# PIC32CM1216JH01048 register map
Vendor: Microchip Technology; Series: PIC32CMJH01; File version: 0
CPU: CM0+ r0p0, little endian, MPU, no FPU, VTOR, 2 interrupt priority bits, 32 interrupts
Registers are 32-bit, read-write, reset 0x0 unless marked. A register's access mark holds for its fields unless they carry their own. Offsets are from the block's base; [hi:lo] are bit positions.

## NVMCTRL — Non-Volatile Memory Controller
Base 0x41004000
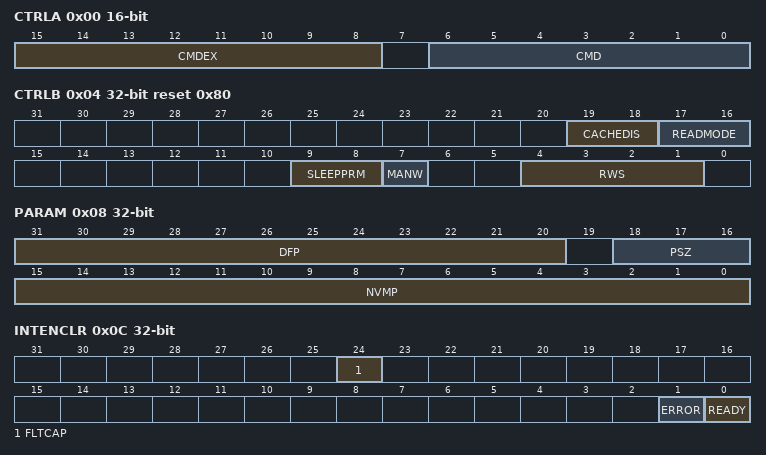
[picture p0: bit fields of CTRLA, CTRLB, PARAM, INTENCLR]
0x00 CTRLA 16-bit — Control A
  [15:8] CMDEX — Command Execution
    165=KEY (Execution Key)
  [6:0] CMD — Command
    2=ER (Erase Row - Erases the row addressed by the ADDR register.); 4=WP (Write Page - Writes the contents of the page buffer to the page addressed by the ADDR register.); 5=EAR (Erase Auxiliary Row - Erases the auxiliary row addressed by the ADDR register. This command can be given only when the security bit is not set and only to the user configuration row.); 6=WAP (Write Auxiliary Page - Writes the contents of the page buffer to the page addressed by the ADDR register. This command can be given only when the security bit is not set and only to the user configuration row.); 26=DFER (Data Flash Erase Row - Erases the row addressed by the ADDR register.); 28=DFWP (Data Flash Write Page - Writes the contents of the page buffer to the page addressed by the ADDR register.); 64=LR (Lock Region - Locks the region containing the address location in the ADDR register.); 65=UR (Unlock Region - Unlocks the region containing the address location in the ADDR register.); 66=SPRM (Sets the power reduction mode.); 67=CPRM (Clears the power reduction mode.); 68=PBC (Page Buffer Clear - Clears the page buffer.); 69=SSB (Set Security Bit - Sets the security bit by writing 0x00 to the first byte in the lockbit row.); 70=INVALL (Invalidate all cache lines.); 127=SCEHL (Set Chip Erase Hard Lock (SCEHL) flash controller command)
0x04 CTRLB reset 0x80 — Control B
  [19:18] CACHEDIS — Cache Disable
    0=CACHE_DF_DIS_MAIN_EN (The Data Flash cache is disabled, the main array cache is enabled); 1=CACHE_DF_DIS_MAIN_DIS (The Data Flash cache is disabled, the main array cache is disabled); 2=CACHE_DF_EN_MAIN_EN (The Data Flash cache is enabled, the main array cache is enabled); 3=CACHE_DF_EN_MAIN_DIS (The Data Flash cache is enabled, the main array cache is disabled)
  [17:16] READMODE — NVM Read Mode
    0=NO_MISS_PENALTY (The NVM Controller (cache system) does not insert wait states on a cache miss. Gives the best system performance.); 1=LOW_POWER (Reduces power consumption of the cache system, but inserts a wait state each time there is a cache miss. This mode may not be relevant if CPU performance is required, as the application will be stalled and may lead to increase run time.); 2=DETERMINISTIC (The cache system ensures that a cache hit or miss takes the same amount of time, determined by the number of programmed flash wait states. This mode can be used for real-time applications that require deterministic execution timings.)
  [9:8] SLEEPPRM — Power Reduction Mode during Sleep
    0=WAKEONACCESS (NVM block enters low-power mode when entering sleep.NVM block exits low-power mode upon first access.); 1=WAKEUPINSTANT (NVM block enters low-power mode when entering sleep.NVM block exits low-power mode when exiting sleep.); 3=DISABLED (Auto power reduction disabled.)
  [7] MANW — Manual Write
  [4:1] RWS — NVM Read Wait States
    0=SINGLE (Single Auto Wait State); 1=HALF (Half Auto Wait State); 2=DUAL (Dual Auto Wait State)
0x08 PARAM — NVM Parameter
  [31:20] DFP — Data Flash Pages
  [18:16] PSZ — Page Size
    0=8 bytes; 1=16 bytes; 2=32 bytes; 3=64 bytes; 4=128 bytes; 5=256 bytes; 6=512 bytes; 7=1024 bytes
  [15:0] NVMP — NVM Pages
0x0C INTENCLR write-1-clears — Interrupt Enable Clear
  [24] FLTCAP — Fault Capture interrupt enable bit Disable
  [1] ERROR — Error Interrupt Enable
  [0] READY — NVM Ready Interrupt Enable
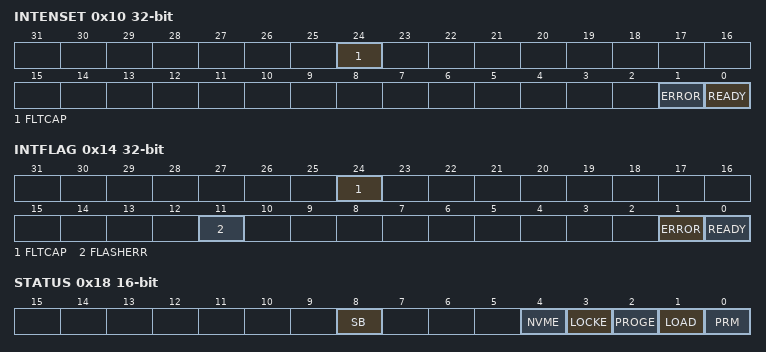
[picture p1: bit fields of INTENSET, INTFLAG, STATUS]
0x10 INTENSET write-1-sets — Interrupt Enable Set
  [24] FLTCAP — Fault Capture interrupt enable bit Enable
  [1] ERROR — Error Interrupt Enable
  [0] READY — NVM Ready Interrupt Enable
0x14 INTFLAG write-1-clears — Interrupt Flag Status and Clear
  [24] FLTCAP — Fault Capture Interrupt
  [11] FLASHERR
  [1] ERROR
    0=No errors have been received since the last clear; 1=At least one error has occurred since the last clear
  [0] READY — NVM Ready
    0=The NVM controller is busy programming or erasing; 1=The NVM controller is ready to accept a new command
0x18 STATUS 16-bit
  [8] SB — Security Bit Status
  [4] NVME — NVM Error
  [3] LOCKE — Lock Error Status
  [2] PROGE — Programming Error Status
  [1] LOAD — NVM Page Buffer Active Loading
  [0] PRM — Power Reduction Mode
0x1C ADDR — Address
  [21:0] ADDR — NVM Address
0x20 LOCK 16-bit — Lock Section
  [15:0] LOCK — Region Lock Bits
0x28 PBLDATA0 ro reset 0xFFFFFFFF — Page Buffer Load Data 0
  [31:0] PBLDATA — Page Buffer Load Data
0x2C PBLDATA1 ro reset 0xFFFFFFFF — Page Buffer Load Data 1
  [31:0] PBLDATA — Page Buffer Load Data

## Notices in the file
Copyright (c) 2026 Microchip Technology Inc.
SPDX-License-Identifier: Apache-2.0
Licensed under the Apache License, Version 2.0 (the "License");
you may not use this file except in compliance with the License.
You may obtain a copy of the License at
http://www.apache.org/licenses/LICENSE-2.0
Unless required by applicable law or agreed to in writing, software
distributed under the License is distributed on an "AS IS" BASIS,
WITHOUT WARRANTIES OR CONDITIONS OF ANY KIND, either express or implied.
See the License for the specific language governing permissions and
limitations under the License.
